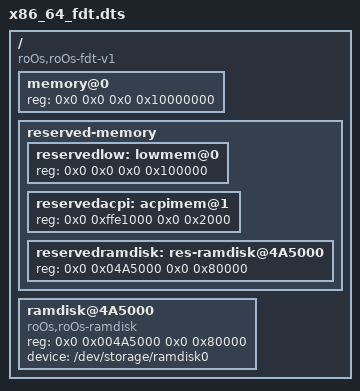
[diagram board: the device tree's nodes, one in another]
/dts-v1/;

/ {
    compatible = "roOs,roOs-fdt-v1";

    #address-cells = <2>;
    #size-cells = <2>;

    memory@0 {
        #address-cells = <2>;
        #size-cells = <2>;

        device_type = "memory";
        reg = <0x0 0x0 0x0 0x10000000>;
    };

    reserved-memory {
        #address-cells = <2>;
        #size-cells = <2>;
        ranges;
        reservedlow: lowmem@0 {
            reg = <0x0 0x0 0x0 0x100000>;
        };
        reservedacpi: acpimem@1 {
            reg = <0x0 0xffe1000 0x0 0x2000>;
        };
        reservedramdisk: res-ramdisk@4A5000 {
            reg = <0x0 0x04A5000 0x0 0x80000>;
        };
    };

    ramdisk@4A5000 {
        compatible = "roOs,roOs-ramdisk";
        reg = <0x0 0x004A5000 0x0 0x80000>;
        device = "/dev/storage/ramdisk0";
    };
};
